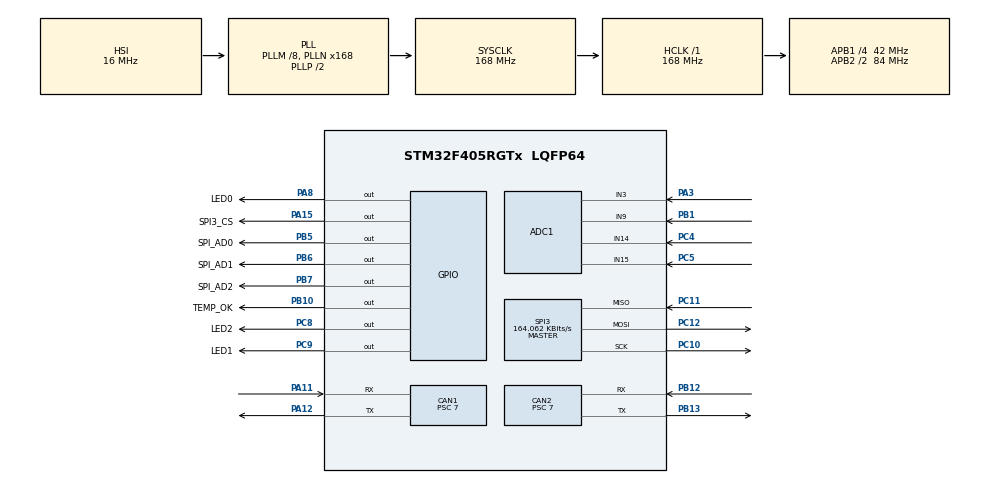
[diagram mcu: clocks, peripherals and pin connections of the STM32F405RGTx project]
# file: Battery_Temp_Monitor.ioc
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ADC1.Channel-0\#ChannelRegularConversion=ADC_CHANNEL_3
ADC1.ClockPrescaler=ADC_CLOCK_SYNC_PCLK_DIV4
ADC1.ContinuousConvMode=ENABLE
ADC1.DMAContinuousRequests=ENABLE
ADC1.NbrOfConversion=1
ADC1.NbrOfConversionFlag=1
ADC1.Rank-0\#ChannelRegularConversion=1
ADC1.SamplingTime-0\#ChannelRegularConversion=ADC_SAMPLETIME_3CYCLES
ADC1.master=1
ADC2.Channel-0\#ChannelRegularConversion=ADC_CHANNEL_3
ADC2.ClockPrescaler=ADC_CLOCK_SYNC_PCLK_DIV4
ADC2.NbrOfConversionFlag=1
ADC2.Rank-0\#ChannelRegularConversion=1
ADC2.SamplingTime-0\#ChannelRegularConversion=ADC_SAMPLETIME_3CYCLES
ADC3.Channel-0\#ChannelRegularConversion=ADC_CHANNEL_3
ADC3.ClockPrescaler=ADC_CLOCK_SYNC_PCLK_DIV4
ADC3.NbrOfConversionFlag=1
ADC3.Rank-0\#ChannelRegularConversion=1
ADC3.SamplingTime-0\#ChannelRegularConversion=ADC_SAMPLETIME_3CYCLES
CAN1.BS1=CAN_BS1_3TQ
CAN1.BS2=CAN_BS2_2TQ
CAN1.CalculateBaudRate=1000000
CAN1.CalculateTimeBit=999.99
CAN1.CalculateTimeQuantum=166.66666666666669
CAN1.Prescaler=7
CAN2.BS1=CAN_BS1_3TQ
CAN2.BS2=CAN_BS2_2TQ
CAN2.CalculateBaudRate=1000000
CAN2.CalculateTimeBit=999.99
CAN2.CalculateTimeQuantum=166.66666666666669
CAN2.NART=ENABLE
CAN2.Prescaler=7
Dma.ADC1.0.Direction=DMA_PERIPH_TO_MEMORY
Dma.ADC1.0.FIFOMode=DMA_FIFOMODE_DISABLE
Dma.ADC1.0.Instance=DMA2_Stream0
Dma.ADC1.0.MemDataAlignment=DMA_MDATAALIGN_WORD
Dma.ADC1.0.MemInc=DMA_MINC_ENABLE
Dma.ADC1.0.Mode=DMA_CIRCULAR
Dma.ADC1.0.PeriphDataAlignment=DMA_PDATAALIGN_WORD
Dma.ADC1.0.PeriphInc=DMA_PINC_DISABLE
Dma.ADC1.0.Priority=DMA_PRIORITY_LOW
Dma.Request0=ADC1
Mcu.Family=STM32F4
Mcu.Name=STM32F405RGTx
Mcu.Package=LQFP64
NVIC.CAN1_RX0_IRQn=true\:0\:0\:false\:false\:true\:true\:true
NVIC.CAN1_RX1_IRQn=true\:0\:0\:false\:false\:true\:true\:true
NVIC.CAN2_RX0_IRQn=true\:0\:0\:false\:false\:true\:true\:true
NVIC.CAN2_RX1_IRQn=true\:0\:0\:false\:false\:true\:true\:true
NVIC.DMA2_Stream0_IRQn=true\:0\:0\:false\:false\:true\:false\:true
NVIC.PriorityGroup=NVIC_PRIORITYGROUP_4
PA11.Mode=CAN_Activate
PA11.Signal=CAN1_RX
PA12.Mode=CAN_Activate
PA12.Signal=CAN1_TX
PA13.Mode=Trace_Asynchronous_SW
PA13.Signal=SYS_JTMS-SWDIO
PA14.Mode=Trace_Asynchronous_SW
PA14.Signal=SYS_JTCK-SWCLK
PA15.GPIO_Label=SPI3_CS
PA15.Signal=GPIO_Output
PA3.Signal=ADCx_IN3
PA8.GPIO_Label=LED0
PA8.Signal=GPIO_Output
PB1.Signal=ADCx_IN9
PB10.GPIO_Label=TEMP_OK
PB10.Signal=GPIO_Output
PB12.GPIO_PuPd=GPIO_NOPULL
PB12.Mode=CAN_Activate
PB12.Signal=CAN2_RX
PB13.Mode=CAN_Activate
PB13.Signal=CAN2_TX
PB3.Mode=Trace_Asynchronous_SW
PB3.Signal=SYS_JTDO-SWO
PB5.GPIO_Label=SPI_AD0
PB5.Signal=GPIO_Output
PB6.GPIO_Label=SPI_AD1
PB6.Signal=GPIO_Output
PB7.GPIO_Label=SPI_AD2
PB7.Signal=GPIO_Output
PC10.Mode=Full_Duplex_Master
PC10.Signal=SPI3_SCK
PC11.GPIO_PuPd=GPIO_PULLDOWN
PC11.Mode=Full_Duplex_Master
PC11.Signal=SPI3_MISO
PC12.Mode=Full_Duplex_Master
PC12.Signal=SPI3_MOSI
PC4.Signal=ADCx_IN14
PC5.Signal=ADCx_IN15
PC8.GPIO_Label=LED2
PC8.Signal=GPIO_Output
PC9.GPIO_Label=LED1
PC9.Signal=GPIO_Output
PH0-OSC_IN.Mode=HSE-External-Oscillator
PH0-OSC_IN.Signal=RCC_OSC_IN
PH1-OSC_OUT.Mode=HSE-External-Oscillator
PH1-OSC_OUT.Signal=RCC_OSC_OUT
ProjectManager.HeapSize=0x200
ProjectManager.StackSize=0x400
ProjectManager.TargetToolchain=STM32CubeIDE
RCC.48MHZClocksFreq_Value=48000000
RCC.AHBFreq_Value=168000000
RCC.APB1CLKDivider=RCC_HCLK_DIV4
RCC.APB1Freq_Value=42000000
RCC.APB1TimFreq_Value=84000000
RCC.APB2CLKDivider=RCC_HCLK_DIV2
RCC.APB2Freq_Value=84000000
RCC.APB2TimFreq_Value=168000000
RCC.CortexFreq_Value=168000000
RCC.EnbaleCSS=true
RCC.HCLKFreq_Value=168000000
RCC.HSE_VALUE=8000000
RCC.HSI_VALUE=16000000
RCC.LSE_VALUE=32768
RCC.PLLM=8
RCC.PLLN=168
RCC.PLLQ=7
RCC.SYSCLKFreq_VALUE=168000000
RCC.SYSCLKSource=RCC_SYSCLKSOURCE_PLLCLK
RCC.VCOOutputFreq_Value=336000000
SH.ADCx_IN14.0=ADC1_IN14,IN14
SH.ADCx_IN15.0=ADC1_IN15,IN15
SH.ADCx_IN3.0=ADC1_IN3,IN3
SH.ADCx_IN3.1=ADC2_IN3,IN3
SH.ADCx_IN3.2=ADC3_IN3,IN3
SH.ADCx_IN9.0=ADC1_IN9,IN9
SPI3.BaudRatePrescaler=SPI_BAUDRATEPRESCALER_256
SPI3.CalculateBaudRate=164.062 KBits/s
SPI3.Direction=SPI_DIRECTION_2LINES
SPI3.Mode=SPI_MODE_MASTER
SPI3.VirtualType=VM_MASTER
TIM12.Prescaler=167
TIM3.Channel-Input_Capture1_from_TRC=TIM_CHANNEL_1
VP_CRC_VS_CRC.Mode=CRC_Activate
VP_TIM12_VS_ClockSourceINT.Mode=Internal
VP_TIM3_VS_ClockSourceINT.Mode=Internal
board=custom

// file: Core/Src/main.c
/* USER CODE BEGIN Header */
/**
  ******************************************************************************
  * @file           : main.c
  * @brief          : Main program body
  ******************************************************************************
  * @attention
  *
  * <h2><center>&copy; Copyright (c) 2020 STMicroelectronics.
  * All rights reserved.</center></h2>
  *
  * This software component is licensed by ST under BSD 3-Clause license,
  * the "License"; You may not use this file except in compliance with the
  * License. You may obtain a copy of the License at:
  *                        opensource.org/licenses/BSD-3-Clause
  *
  ******************************************************************************
  */
/* USER CODE END Header */
#include "main.h"
#include "adc.h"
#include "can.h"
#include "crc.h"
#include "dma.h"
#include "spi.h"
#include "tim.h"
#include "gpio.h"

void SystemClock_Config(void);

int main(void)
{

  /* MCU Configuration--------------------------------------------------------*/

  /* Reset of all peripherals, Initializes the Flash interface and the Systick. */
  HAL_Init();

  /* Configure the system clock */
  SystemClock_Config();

  /* Initialize all configured peripherals */
  MX_GPIO_Init();
  MX_DMA_Init();
  MX_ADC1_Init();
  MX_ADC2_Init();
  MX_ADC3_Init();
  MX_CRC_Init();
  MX_TIM3_Init();
  MX_TIM12_Init();
  MX_CAN1_Init();
  MX_SPI3_Init();
  MX_CAN2_Init();
  /* USER CODE BEGIN 2 */
  GAS_Scheduler_init();
  /* USER CODE END 2 */

  /* Infinite loop */
  while (1)
  {

    /* USER CODE BEGIN 3 */
		 GAS_Scheduler();
  }
  /* USER CODE END 3 */
}

void SystemClock_Config(void)
{
  RCC_OscInitTypeDef RCC_OscInitStruct = {0};
  RCC_ClkInitTypeDef RCC_ClkInitStruct = {0};

  /** Configure the main internal regulator output voltage
  */
  __HAL_RCC_PWR_CLK_ENABLE();
  __HAL_PWR_VOLTAGESCALING_CONFIG(PWR_REGULATOR_VOLTAGE_SCALE1);
  /** Initializes the RCC Oscillators according to the specified parameters
  * in the RCC_OscInitTypeDef structure.
  */
  RCC_OscInitStruct.OscillatorType = RCC_OSCILLATORTYPE_HSI;
  RCC_OscInitStruct.HSIState = RCC_HSI_ON;
  RCC_OscInitStruct.HSICalibrationValue = RCC_HSICALIBRATION_DEFAULT;
  RCC_OscInitStruct.PLL.PLLState = RCC_PLL_ON;
  RCC_OscInitStruct.PLL.PLLSource = RCC_PLLSOURCE_HSI;
  RCC_OscInitStruct.PLL.PLLM = 8;
  RCC_OscInitStruct.PLL.PLLN = 168;
  RCC_OscInitStruct.PLL.PLLP = RCC_PLLP_DIV2;
  RCC_OscInitStruct.PLL.PLLQ = 7;
  if (HAL_RCC_OscConfig(&RCC_OscInitStruct) != HAL_OK)
  {
    Error_Handler();
  }
  /** Initializes the CPU, AHB and APB buses clocks
  */
  RCC_ClkInitStruct.ClockType = RCC_CLOCKTYPE_HCLK|RCC_CLOCKTYPE_SYSCLK
                              |RCC_CLOCKTYPE_PCLK1|RCC_CLOCKTYPE_PCLK2;
  RCC_ClkInitStruct.SYSCLKSource = RCC_SYSCLKSOURCE_PLLCLK;
  RCC_ClkInitStruct.AHBCLKDivider = RCC_SYSCLK_DIV1;
  RCC_ClkInitStruct.APB1CLKDivider = RCC_HCLK_DIV4;
  RCC_ClkInitStruct.APB2CLKDivider = RCC_HCLK_DIV2;

  if (HAL_RCC_ClockConfig(&RCC_ClkInitStruct, FLASH_LATENCY_5) != HAL_OK)
  {
    Error_Handler();
  }
  /** Enables the Clock Security System
  */
  HAL_RCC_EnableCSS();
}

void Error_Handler(void)
{
  /* USER CODE BEGIN Error_Handler_Debug */
	HAL_GPIO_WritePin(LED0_GPIO_Port,LED0_Pin,1);
	HAL_GPIO_WritePin(LED1_GPIO_Port,LED1_Pin,0);
	HAL_GPIO_WritePin(LED2_GPIO_Port,LED2_Pin,0);
  /* User can add his own implementation to report the HAL error return state */
  __disable_irq();
  while (1)
  {

  }
  /* USER CODE END Error_Handler_Debug */
}

/************************ (C) COPYRIGHT STMicroelectronics *****END OF FILE****/
